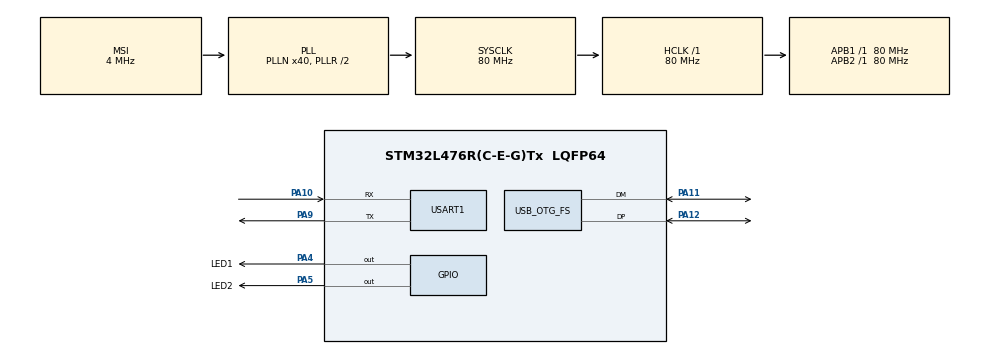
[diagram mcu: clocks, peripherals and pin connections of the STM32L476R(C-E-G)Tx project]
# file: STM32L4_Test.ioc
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Mcu.Family=STM32L4
Mcu.Name=STM32L476R(C-E-G)Tx
Mcu.Package=LQFP64
NVIC.OTG_FS_IRQn=true\:0\:0\:false\:false\:true\:false
NVIC.PriorityGroup=NVIC_PRIORITYGROUP_4
NVIC.USART1_IRQn=true\:0\:0\:false\:false\:true\:true
PA10.Mode=Asynchronous
PA10.Signal=USART1_RX
PA11.Mode=Device_Only
PA11.Signal=USB_OTG_FS_DM
PA12.Mode=Device_Only
PA12.Signal=USB_OTG_FS_DP
PA13\ (JTMS-SWDIO).Mode=Serial_Wire
PA13\ (JTMS-SWDIO).Signal=SYS_JTMS-SWDIO
PA14\ (JTCK-SWCLK).Mode=Serial_Wire
PA14\ (JTCK-SWCLK).Signal=SYS_JTCK-SWCLK
PA4.GPIO_Label=LED1
PA4.Signal=GPIO_Output
PA5.GPIO_Label=LED2
PA5.Signal=GPIO_Output
PA9.Mode=Asynchronous
PA9.Signal=USART1_TX
ProjectManager.HeapSize=0x200
ProjectManager.StackSize=0x400
ProjectManager.TargetToolchain=TrueSTUDIO
RCC.ADCFreq_Value=48000000
RCC.AHBFreq_Value=80000000
RCC.APB1Freq_Value=80000000
RCC.APB1TimFreq_Value=80000000
RCC.APB2Freq_Value=80000000
RCC.APB2TimFreq_Value=80000000
RCC.CortexFreq_Value=80000000
RCC.HCLKFreq_Value=80000000
RCC.HSE_VALUE=16000000
RCC.HSI_VALUE=16000000
RCC.LSE_VALUE=32768
RCC.MSICalibrationValue=0
RCC.MSI_VALUE=4000000
RCC.PLLN=40
RCC.PLLQ=RCC_PLLQ_DIV4
RCC.PLLSAI1N=24
RCC.RTCClockSelection=RCC_RTCCLKSOURCE_LSE
RCC.SYSCLKFreq_VALUE=80000000
RCC.SYSCLKSource=RCC_SYSCLKSOURCE_PLLCLK
RCC.USBFreq_Value=48000000
RCC.VCOOutputFreq_Value=160000000
USART1.VirtualMode-Asynchronous=VM_ASYNC
USART1.WordLength=WORDLENGTH_8B
USB_DEVICE.CLASS_NAME_FS=CUSTOMHID
USB_DEVICE.PID_CUSTOMHID_FS=22352
USB_DEVICE.PRODUCT_STRING_CUSTOMHID_FS=STM32 Custom Human interface
USB_DEVICE.USBD_CUSTOMHID_OUTREPORT_BUF_SIZE=8
USB_DEVICE.USBD_CUSTOM_HID_REPORT_DESC_SIZE=38
USB_DEVICE.USBD_LPM_ENABLED=0
USB_DEVICE.VirtualMode=CustomHid
USB_DEVICE.VirtualModeFS=Custom_Hid_FS
USB_OTG_FS.VirtualMode=Device_Only
VP_USB_DEVICE_VS_USB_DEVICE_CUSTOM_HID_FS.Mode=CUSTOM_HID_FS
board=STM32L4_Test

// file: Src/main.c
/**
  ******************************************************************************
  * @file           : main.c
  * @brief          : Main program body
  ******************************************************************************
  * This notice applies to any and all portions of this file
  * that are not between comment pairs USER CODE BEGIN and
  * USER CODE END. Other portions of this file, whether
  * inserted by the user or by software development tools
  * are owned by their respective copyright owners.
  *
  * Copyright (c) 2018 STMicroelectronics International N.V.
  * All rights reserved.
  *
  * Redistribution and use in source and binary forms, with or without
  * modification, are permitted, provided that the following conditions are met:
  *
  * 1. Redistribution of source code must retain the above copyright notice,
  *    this list of conditions and the following disclaimer.
  * 2. Redistributions in binary form must reproduce the above copyright notice,
  *    this list of conditions and the following disclaimer in the documentation
  *    and/or other materials provided with the distribution.
  * 3. Neither the name of STMicroelectronics nor the names of other
  *    contributors to this software may be used to endorse or promote products
  *    derived from this software without specific written permission.
  * 4. This software, including modifications and/or derivative works of this
  *    software, must execute solely and exclusively on microcontroller or
  *    microprocessor devices manufactured by or for STMicroelectronics.
  * 5. Redistribution and use of this software other than as permitted under
  *    this license is void and will automatically terminate your rights under
  *    this license.
  *
  * THIS SOFTWARE IS PROVIDED BY STMICROELECTRONICS AND CONTRIBUTORS "AS IS"
  * AND ANY EXPRESS, IMPLIED OR STATUTORY WARRANTIES, INCLUDING, BUT NOT
  * LIMITED TO, THE IMPLIED WARRANTIES OF MERCHANTABILITY, FITNESS FOR A
  * PARTICULAR PURPOSE AND NON-INFRINGEMENT OF THIRD PARTY INTELLECTUAL PROPERTY
  * RIGHTS ARE DISCLAIMED TO THE FULLEST EXTENT PERMITTED BY LAW. IN NO EVENT
  * SHALL STMICROELECTRONICS OR CONTRIBUTORS BE LIABLE FOR ANY DIRECT, INDIRECT,
  * INCIDENTAL, SPECIAL, EXEMPLARY, OR CONSEQUENTIAL DAMAGES (INCLUDING, BUT NOT
  * LIMITED TO, PROCUREMENT OF SUBSTITUTE GOODS OR SERVICES; LOSS OF USE, DATA,
  * OR PROFITS; OR BUSINESS INTERRUPTION) HOWEVER CAUSED AND ON ANY THEORY OF
  * LIABILITY, WHETHER IN CONTRACT, STRICT LIABILITY, OR TORT (INCLUDING
  * NEGLIGENCE OR OTHERWISE) ARISING IN ANY WAY OUT OF THE USE OF THIS SOFTWARE,
  * EVEN IF ADVISED OF THE POSSIBILITY OF SUCH DAMAGE.
  *
  ******************************************************************************
  */
#include "main.h"
#include "stm32l4xx_hal.h"
#include "usart.h"
#include "usb_device.h"
#include "gpio.h"

/* USER CODE BEGIN Includes */
#include "usbd_customhid.h"
#include <string.h>
#include <stdlib.h>
/* USER CODE END Includes */

/* USER CODE BEGIN PV */
/* Private variables ---------------------------------------------------------*/

/* USER CODE END PV */

void SystemClock_Config(void);

/* USER CODE BEGIN PFP */
/* Private function prototypes -----------------------------------------------*/
extern USBD_HandleTypeDef hUsbDeviceFS;
extern USBD_DescriptorsTypeDef FS_Desc;
extern USBD_CUSTOM_HID_ItfTypeDef  USBD_CustomHID_fops_FS;
/* USER CODE END PFP */

int main(void)
{

  /* MCU Configuration----------------------------------------------------------*/

  /* Reset of all peripherals, Initializes the Flash interface and the Systick. */
  HAL_Init();

  /* Configure the system clock */
  SystemClock_Config();

  /* Initialize all configured peripherals */
  MX_GPIO_Init();
  MX_USART1_UART_Init();
  MX_USB_DEVICE_Init();
  /* USER CODE BEGIN 2 */
  __HAL_UART_ENABLE_IT(&huart1, UART_IT_RXNE);
  //HAL_GPIO_TogglePin(GPIOA,LED1_Pin);

  /* USER CODE END 2 */

  /* Infinite loop */
  while (1)
  {

  /* USER CODE BEGIN 3 */
	 // HAL_GPIO_TogglePin(GPIOA,LED1_Pin);
	 // HAL_GPIO_TogglePin(GPIOA,LED2_Pin);
	 // HAL_Delay(1000);
  }
  /* USER CODE END 3 */

}

void SystemClock_Config(void)
{

  RCC_OscInitTypeDef RCC_OscInitStruct;
  RCC_ClkInitTypeDef RCC_ClkInitStruct;
  RCC_PeriphCLKInitTypeDef PeriphClkInit;

    /**Initializes the CPU, AHB and APB busses clocks
    */
  RCC_OscInitStruct.OscillatorType = RCC_OSCILLATORTYPE_MSI;
  RCC_OscInitStruct.MSIState = RCC_MSI_ON;
  RCC_OscInitStruct.MSICalibrationValue = 0;
  RCC_OscInitStruct.MSIClockRange = RCC_MSIRANGE_6;
  RCC_OscInitStruct.PLL.PLLState = RCC_PLL_ON;
  RCC_OscInitStruct.PLL.PLLSource = RCC_PLLSOURCE_MSI;
  RCC_OscInitStruct.PLL.PLLN = 40;
  RCC_OscInitStruct.PLL.PLLP = RCC_PLLP_DIV7;
  RCC_OscInitStruct.PLL.PLLQ = RCC_PLLQ_DIV4;
  RCC_OscInitStruct.PLL.PLLR = RCC_PLLR_DIV2;
  if (HAL_RCC_OscConfig(&RCC_OscInitStruct) != HAL_OK)
  {
    _Error_Handler(__FILE__, __LINE__);
  }

    /**Initializes the CPU, AHB and APB busses clocks
    */
  RCC_ClkInitStruct.ClockType = RCC_CLOCKTYPE_HCLK|RCC_CLOCKTYPE_SYSCLK
                              |RCC_CLOCKTYPE_PCLK1|RCC_CLOCKTYPE_PCLK2;
  RCC_ClkInitStruct.SYSCLKSource = RCC_SYSCLKSOURCE_PLLCLK;
  RCC_ClkInitStruct.AHBCLKDivider = RCC_SYSCLK_DIV1;
  RCC_ClkInitStruct.APB1CLKDivider = RCC_HCLK_DIV1;
  RCC_ClkInitStruct.APB2CLKDivider = RCC_HCLK_DIV1;

  if (HAL_RCC_ClockConfig(&RCC_ClkInitStruct, FLASH_LATENCY_4) != HAL_OK)
  {
    _Error_Handler(__FILE__, __LINE__);
  }

  PeriphClkInit.PeriphClockSelection = RCC_PERIPHCLK_USART1|RCC_PERIPHCLK_USB;
  PeriphClkInit.Usart1ClockSelection = RCC_USART1CLKSOURCE_PCLK2;
  PeriphClkInit.UsbClockSelection = RCC_USBCLKSOURCE_PLLSAI1;
  PeriphClkInit.PLLSAI1.PLLSAI1Source = RCC_PLLSOURCE_MSI;
  PeriphClkInit.PLLSAI1.PLLSAI1M = 1;
  PeriphClkInit.PLLSAI1.PLLSAI1N = 24;
  PeriphClkInit.PLLSAI1.PLLSAI1P = RCC_PLLP_DIV7;
  PeriphClkInit.PLLSAI1.PLLSAI1Q = RCC_PLLQ_DIV2;
  PeriphClkInit.PLLSAI1.PLLSAI1R = RCC_PLLR_DIV2;
  PeriphClkInit.PLLSAI1.PLLSAI1ClockOut = RCC_PLLSAI1_48M2CLK;
  if (HAL_RCCEx_PeriphCLKConfig(&PeriphClkInit) != HAL_OK)
  {
    _Error_Handler(__FILE__, __LINE__);
  }

    /**Configure the main internal regulator output voltage
    */
  if (HAL_PWREx_ControlVoltageScaling(PWR_REGULATOR_VOLTAGE_SCALE1) != HAL_OK)
  {
    _Error_Handler(__FILE__, __LINE__);
  }

    /**Configure the Systick interrupt time
    */
  HAL_SYSTICK_Config(HAL_RCC_GetHCLKFreq()/1000);

    /**Configure the Systick
    */
  HAL_SYSTICK_CLKSourceConfig(SYSTICK_CLKSOURCE_HCLK);

  /* SysTick_IRQn interrupt configuration */
  HAL_NVIC_SetPriority(SysTick_IRQn, 0, 0);
}

void _Error_Handler(char *file, int line)
{
  while(1)
  {
  }
}

/************************ (C) COPYRIGHT STMicroelectronics *****END OF FILE****/
